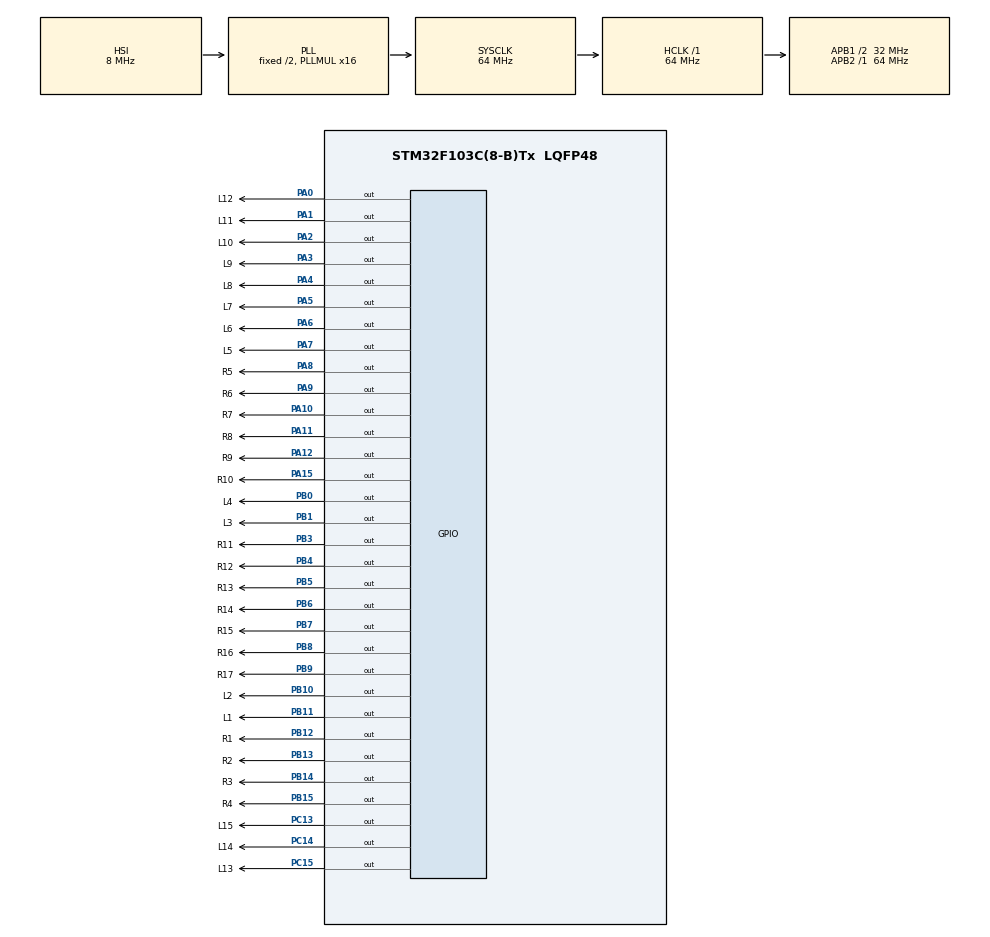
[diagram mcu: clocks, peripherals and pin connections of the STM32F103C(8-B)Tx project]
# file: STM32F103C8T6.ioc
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Mcu.Family=STM32F1
Mcu.Name=STM32F103C(8-B)Tx
Mcu.Package=LQFP48
NVIC.PriorityGroup=NVIC_PRIORITYGROUP_4
PA0-WKUP.GPIO_Label=L12
PA0-WKUP.Signal=GPIO_Output
PA1.GPIO_Label=L11
PA1.Signal=GPIO_Output
PA10.GPIO_Label=R7
PA10.Signal=GPIO_Output
PA11.GPIO_Label=R8
PA11.Signal=GPIO_Output
PA12.GPIO_Label=R9
PA12.Signal=GPIO_Output
PA15.GPIO_Label=R10
PA15.Signal=GPIO_Output
PA2.GPIO_Label=L10
PA2.Signal=GPIO_Output
PA3.GPIO_Label=L9
PA3.Signal=GPIO_Output
PA4.GPIO_Label=L8
PA4.Signal=GPIO_Output
PA5.GPIO_Label=L7
PA5.Signal=GPIO_Output
PA6.GPIO_Label=L6
PA6.Signal=GPIO_Output
PA7.GPIO_Label=L5
PA7.Signal=GPIO_Output
PA8.GPIO_Label=R5
PA8.Signal=GPIO_Output
PA9.GPIO_Label=R6
PA9.Signal=GPIO_Output
PB0.GPIO_Label=L4
PB0.Signal=GPIO_Output
PB1.GPIO_Label=L3
PB1.Signal=GPIO_Output
PB10.GPIO_Label=L2
PB10.Signal=GPIO_Output
PB11.GPIO_Label=L1
PB11.Signal=GPIO_Output
PB12.GPIO_Label=R1
PB12.Signal=GPIO_Output
PB13.GPIO_Label=R2
PB13.Signal=GPIO_Output
PB14.GPIO_Label=R3
PB14.Signal=GPIO_Output
PB15.GPIO_Label=R4
PB15.Signal=GPIO_Output
PB3.GPIO_Label=R11
PB3.Signal=GPIO_Output
PB4.GPIO_Label=R12
PB4.Signal=GPIO_Output
PB5.GPIO_Label=R13
PB5.Signal=GPIO_Output
PB6.GPIO_Label=R14
PB6.Signal=GPIO_Output
PB7.GPIO_Label=R15
PB7.Signal=GPIO_Output
PB8.GPIO_Label=R16
PB8.Signal=GPIO_Output
PB9.GPIO_Label=R17
PB9.Signal=GPIO_Output
PC13-TAMPER-RTC.GPIO_Label=L15
PC13-TAMPER-RTC.Signal=GPIO_Output
PC14-OSC32_IN.GPIO_Label=L14
PC14-OSC32_IN.Signal=GPIO_Output
PC15-OSC32_OUT.GPIO_Label=L13
PC15-OSC32_OUT.Signal=GPIO_Output
ProjectManager.HeapSize=0x200
ProjectManager.StackSize=0x400
ProjectManager.TargetToolchain=STM32CubeIDE
RCC.AHBFreq_Value=64000000
RCC.APB1CLKDivider=RCC_HCLK_DIV2
RCC.APB1Freq_Value=32000000
RCC.APB1TimFreq_Value=64000000
RCC.APB2Freq_Value=64000000
RCC.APB2TimFreq_Value=64000000
RCC.HCLKFreq_Value=64000000
RCC.PLLMUL=RCC_PLL_MUL16
RCC.SYSCLKFreq_VALUE=64000000
RCC.SYSCLKSource=RCC_SYSCLKSOURCE_PLLCLK
RCC.USBFreq_Value=64000000
VP_SYS_VS_ND.Mode=No_Debug
board=custom

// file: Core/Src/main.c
/* USER CODE BEGIN Header */
/**
  ******************************************************************************
  * @file           : main.c
  * @brief          : Main program body
  ******************************************************************************
  * @attention
  *
  * <h2><center>&copy; Copyright (c) 2021 STMicroelectronics.
  * All rights reserved.</center></h2>
  *
  * This software component is licensed by ST under BSD 3-Clause license,
  * the "License"; You may not use this file except in compliance with the
  * License. You may obtain a copy of the License at:
  *                        opensource.org/licenses/BSD-3-Clause
  *
  ******************************************************************************
  */
/* USER CODE END Header */
#include "main.h"

void SystemClock_Config(void);
static void MX_GPIO_Init(void);

int main(void)
{

  /* MCU Configuration--------------------------------------------------------*/

  /* Reset of all peripherals, Initializes the Flash interface and the Systick. */
  HAL_Init();

  /* Configure the system clock */
  SystemClock_Config();

  /* Initialize all configured peripherals */
  MX_GPIO_Init();
  /* USER CODE BEGIN 2 */
  int DelayTime = 100;
  /* USER CODE END 2 */

  /* Infinite loop */
  /* USER CODE BEGIN WHILE */
  while (1)
  {

	  HAL_GPIO_WritePin(L1_GPIO_Port, L1_Pin, 1);
	  HAL_Delay(DelayTime);
	  HAL_GPIO_WritePin(L1_GPIO_Port, L1_Pin, 0);
	  HAL_Delay(DelayTime);

    /* USER CODE END WHILE */

  }
}

void SystemClock_Config(void)
{
  RCC_OscInitTypeDef RCC_OscInitStruct = {0};
  RCC_ClkInitTypeDef RCC_ClkInitStruct = {0};

  /** Initializes the RCC Oscillators according to the specified parameters
  * in the RCC_OscInitTypeDef structure.
  */
  RCC_OscInitStruct.OscillatorType = RCC_OSCILLATORTYPE_HSI;
  RCC_OscInitStruct.HSIState = RCC_HSI_ON;
  RCC_OscInitStruct.HSICalibrationValue = RCC_HSICALIBRATION_DEFAULT;
  RCC_OscInitStruct.PLL.PLLState = RCC_PLL_ON;
  RCC_OscInitStruct.PLL.PLLSource = RCC_PLLSOURCE_HSI_DIV2;
  RCC_OscInitStruct.PLL.PLLMUL = RCC_PLL_MUL16;
  if (HAL_RCC_OscConfig(&RCC_OscInitStruct) != HAL_OK)
  {
    Error_Handler();
  }
  /** Initializes the CPU, AHB and APB buses clocks
  */
  RCC_ClkInitStruct.ClockType = RCC_CLOCKTYPE_HCLK|RCC_CLOCKTYPE_SYSCLK
                              |RCC_CLOCKTYPE_PCLK1|RCC_CLOCKTYPE_PCLK2;
  RCC_ClkInitStruct.SYSCLKSource = RCC_SYSCLKSOURCE_PLLCLK;
  RCC_ClkInitStruct.AHBCLKDivider = RCC_SYSCLK_DIV1;
  RCC_ClkInitStruct.APB1CLKDivider = RCC_HCLK_DIV2;
  RCC_ClkInitStruct.APB2CLKDivider = RCC_HCLK_DIV1;

  if (HAL_RCC_ClockConfig(&RCC_ClkInitStruct, FLASH_LATENCY_2) != HAL_OK)
  {
    Error_Handler();
  }
}

static void MX_GPIO_Init(void)
{
  GPIO_InitTypeDef GPIO_InitStruct = {0};

  /* GPIO Ports Clock Enable */
  __HAL_RCC_GPIOC_CLK_ENABLE();
  __HAL_RCC_GPIOA_CLK_ENABLE();
  __HAL_RCC_GPIOB_CLK_ENABLE();

  /*Configure GPIO pin Output Level */
  HAL_GPIO_WritePin(GPIOC, L15_Pin|L14_Pin|L13_Pin, GPIO_PIN_RESET);

  /*Configure GPIO pin Output Level */
  HAL_GPIO_WritePin(GPIOA, L12_Pin|L11_Pin|L10_Pin|L9_Pin
                          |L8_Pin|L7_Pin|L6_Pin|L5_Pin
                          |R5_Pin|R6_Pin|R7_Pin|R8_Pin
                          |R9_Pin|R10_Pin, GPIO_PIN_RESET);

  /*Configure GPIO pin Output Level */
  HAL_GPIO_WritePin(GPIOB, L4_Pin|L3_Pin|L2_Pin|L1_Pin
                          |R1_Pin|R2_Pin|R3_Pin|R4_Pin
                          |R11_Pin|R12_Pin|R13_Pin|R14_Pin
                          |R15_Pin|R16_Pin|R17_Pin, GPIO_PIN_RESET);

  /*Configure GPIO pins : L15_Pin L14_Pin L13_Pin */
  GPIO_InitStruct.Pin = L15_Pin|L14_Pin|L13_Pin;
  GPIO_InitStruct.Mode = GPIO_MODE_OUTPUT_PP;
  GPIO_InitStruct.Pull = GPIO_NOPULL;
  GPIO_InitStruct.Speed = GPIO_SPEED_FREQ_LOW;
  HAL_GPIO_Init(GPIOC, &GPIO_InitStruct);

  /*Configure GPIO pins : L12_Pin L11_Pin L10_Pin L9_Pin
                           L8_Pin L7_Pin L6_Pin L5_Pin
                           R5_Pin R6_Pin R7_Pin R8_Pin
                           R9_Pin R10_Pin */
  GPIO_InitStruct.Pin = L12_Pin|L11_Pin|L10_Pin|L9_Pin
                          |L8_Pin|L7_Pin|L6_Pin|L5_Pin
                          |R5_Pin|R6_Pin|R7_Pin|R8_Pin
                          |R9_Pin|R10_Pin;
  GPIO_InitStruct.Mode = GPIO_MODE_OUTPUT_PP;
  GPIO_InitStruct.Pull = GPIO_NOPULL;
  GPIO_InitStruct.Speed = GPIO_SPEED_FREQ_LOW;
  HAL_GPIO_Init(GPIOA, &GPIO_InitStruct);

  /*Configure GPIO pins : L4_Pin L3_Pin L2_Pin L1_Pin
                           R1_Pin R2_Pin R3_Pin R4_Pin
                           R11_Pin R12_Pin R13_Pin R14_Pin
                           R15_Pin R16_Pin R17_Pin */
  GPIO_InitStruct.Pin = L4_Pin|L3_Pin|L2_Pin|L1_Pin
                          |R1_Pin|R2_Pin|R3_Pin|R4_Pin
                          |R11_Pin|R12_Pin|R13_Pin|R14_Pin
                          |R15_Pin|R16_Pin|R17_Pin;
  GPIO_InitStruct.Mode = GPIO_MODE_OUTPUT_PP;
  GPIO_InitStruct.Pull = GPIO_NOPULL;
  GPIO_InitStruct.Speed = GPIO_SPEED_FREQ_LOW;
  HAL_GPIO_Init(GPIOB, &GPIO_InitStruct);

}

void Error_Handler(void)
{
  __disable_irq();
  while (1)
  {
  }
}

/************************ (C) COPYRIGHT STMicroelectronics *****END OF FILE****/
